VERSION 0

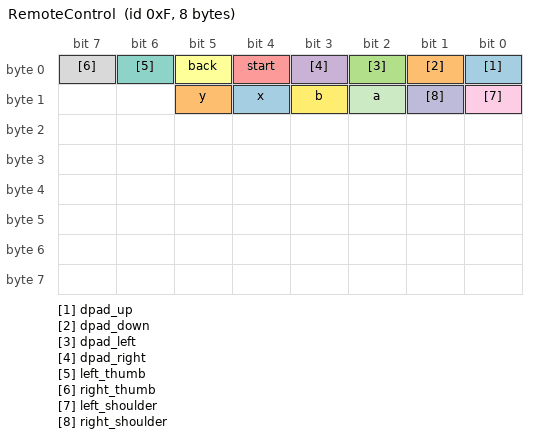
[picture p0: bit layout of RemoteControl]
BO_ 15 RemoteControl: 8
  SG_ dpad_up : 0|1@0+ (1,0) [0|1] ""
  SG_ dpad_down : 1|1@0+ (1,0) [0|1] ""
  SG_ dpad_left : 2|1@0+ (1,0) [0|1] ""
  SG_ dpad_right : 3|1@0+ (1,0) [0|1] ""
  SG_ start : 4|1@0+ (1,0) [0|1] ""
  SG_ back : 5|1@0+ (1,0) [0|1] ""
  SG_ left_thumb : 6|1@0+ (1,0) [0|1] ""
  SG_ right_thumb : 7|1@0+ (1,0) [0|1] ""
  SG_ left_shoulder : 8|1@0+ (1,0) [0|1] ""
  SG_ right_shoulder : 9|1@0+ (1,0) [0|1] ""
  SG_ a : 10|1@0+ (1,0) [0|1] ""
  SG_ b : 11|1@0+ (1,0) [0|1] ""
  SG_ x : 12|1@0+ (1,0) [0|1] ""
  SG_ y : 13|1@0+ (1,0) [0|1] ""
  SG_ left_trigger 15|8@0+ (1,0) [0|255] ""
  SG_ right_trigger 23|8@0+ (1,0) [0|255] ""
  SG_ thumb_left_x 31|8@0+ (1,0) [0|255] ""
  SG_ thumb_left_y 39|8@0+ (1,0) [0|255] ""
  SG_ thumb_right_x 47|8@0+ (1,0) [0|255] ""
  SG_ thumb_right_y 55|8@0+ (1,0) [0|255] ""
